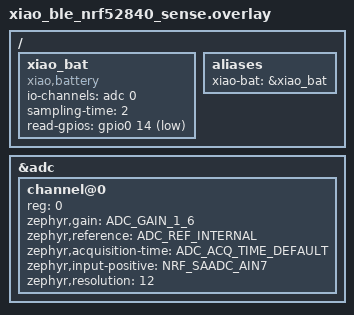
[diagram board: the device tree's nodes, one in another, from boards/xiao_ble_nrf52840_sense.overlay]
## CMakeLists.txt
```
# SPDX-License-Identifier: Apache-2.0

cmake_minimum_required(VERSION 3.20.0)
list(APPEND ZEPHYR_EXTRA_MODULES ${CMAKE_CURRENT_SOURCE_DIR}/../drivers)
find_package(Zephyr REQUIRED HINTS $ENV{ZEPHYR_BASE})
target_include_directories(app PRIVATE ${CMAKE_CURRENT_SOURCE_DIR}/../include)

project(project-helm)

if(DEFINED ID)
    zephyr_compile_definitions(NODE_ID=${ID})
endif()

FILE(GLOB app_sources src/*.c)
target_sources(app PRIVATE
    ${app_sources}
)
```

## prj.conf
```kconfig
# Bluetooth stuff
CONFIG_BT=y
CONFIG_BT_PERIPHERAL=y      # for NUS
CONFIG_BT_ZEPHYR_NUS=y      # for NUS
CONFIG_BT_OBSERVER=y        # for scanning
CONFIG_BT_BROADCASTER=y
CONFIG_BT_EXT_ADV=y

CONFIG_BT_FILTER_ACCEPT_LIST=y # Filtering
CONFIG_BT_MAX_CONN=1

CONFIG_BT_USER_DATA_LEN_UPDATE=y
CONFIG_BT_CTLR_DATA_LENGTH_MAX=251
CONFIG_BT_BUF_ACL_RX_SIZE=251
CONFIG_BT_BUF_ACL_TX_SIZE=251
CONFIG_BT_L2CAP_TX_MTU=247

# Power management
CONFIG_REBOOT=y
CONFIG_PM_DEVICE=y
CONFIG_PM_DEVICE_RUNTIME=y

# LSM6DSL Accelerometer
CONFIG_SENSOR=y
CONFIG_I2C=y
CONFIG_LSM6DSL_TRIGGER_GLOBAL_THREAD=y

# Xiao Battery Sensor
CONFIG_ADC=y
CONFIG_XIAO_BATTERY=y
CONFIG_CBPRINTF_FP_SUPPORT=y

# CRC tools to ensure validty of packets
CONFIG_CRC=y

CONFIG_POSIX_API=y
```

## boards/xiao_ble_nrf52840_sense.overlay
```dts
#include <zephyr/dt-bindings/adc/nrf-saadc.h>
#include <zephyr/dt-bindings/adc/adc.h>

/ {
	xiao_bat: xiao_bat {
		compatible = "xiao,battery";
		status = "okay";
		io-channels = <&adc 0>;
		sampling-time = <2>; /* This is in seconds */
		read-gpios = <&gpio0 14 GPIO_ACTIVE_LOW>;
	};

	aliases {
		xiao-bat = &xiao_bat;
	};
};

&adc {
	#address-cells = <1>;
	#size-cells = <0>;

	channel@0 {
		reg = <0>;
		zephyr,gain = "ADC_GAIN_1_6";
		zephyr,reference = "ADC_REF_INTERNAL";
		zephyr,acquisition-time = <ADC_ACQ_TIME_DEFAULT>;
		zephyr,input-positive = <NRF_SAADC_AIN7>;
		zephyr,resolution = <12>;
	};
};
```

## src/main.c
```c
/*
 * Copyright (c) 2026 Jack Cairns, Eden Mehr, Muhammed Abdilrahmin
 *
 * SPDX-License-Identifier: Apache-2.0
 */

#include <zephyr/kernel.h>
#include <zephyr/sys/reboot.h>

#include "gatt.h"
#include "imu.h"
#include <stdint.h>

/* ========================================================================== */
/* Main                                                                       */
/* ========================================================================== */

int main(void)
{
    printk("[INFO] CSSE4011 Project %s Chip\r\n", DEVICE_NAME);

    if (initialise_imu()) {
        goto reboot;
    }

    if (initialise_helm_gatt()) {
        goto reboot;
    }

    printk("[INFO] Mobile node initialization complete\n");
    uint8_t timeout = 0;
    while (1) {
        (am_i_connected()) ? timeout = 0 : timeout++;
        if (timeout >= 30) {
            goto reboot;
        }

        k_sleep(K_SECONDS(1));
    }
    
    return (0);

reboot:
    // sys_reboot doesn't return
    sys_reboot(SYS_REBOOT_WARM);
    return (-1);
}
```

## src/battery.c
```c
/*
 * Copyright (c) 2026 Jack Cairns, Eden Mehr, Muhammed Abdilrahmin
 *
 * SPDX-License-Identifier: Apache-2.0
 */

#include "battery.h"

#include <zephyr/device.h>
#include <zephyr/drivers/sensor.h>

/* ========================================================================== */
/* Devices                                                                    */
/* ========================================================================== */

static const struct device *const xiao_battery = DEVICE_DT_GET_ONE(xiao_battery);

/* ========================================================================== */
/* Initialisation and settings                                                */
/* ========================================================================== */

int get_battery_voltage(double *value)
{
    if (!device_is_ready(xiao_battery)) {
        printk("[ERROR] Unable to get xiao battery\n");
        return (-1);
    }

    struct sensor_value sensor_voltage;
    sensor_sample_fetch_chan(xiao_battery, SENSOR_CHAN_VOLTAGE);
    sensor_channel_get(xiao_battery, SENSOR_CHAN_VOLTAGE, &sensor_voltage);

    *value = sensor_value_to_double(&sensor_voltage);
    return (0);
}

int get_battery_charge(int32_t *value)
{
    if (!device_is_ready(xiao_battery)) {
        printk("[ERROR] Unable to get xiao battery\n");
        return (-1);
    }

    struct sensor_value sensor_charge;
    sensor_sample_fetch_chan(xiao_battery, SENSOR_CHAN_GAUGE_STATE_OF_CHARGE);
    sensor_channel_get(xiao_battery, SENSOR_CHAN_GAUGE_STATE_OF_CHARGE, &sensor_charge);

    *value = sensor_charge.val1;
    return (0);
}
```

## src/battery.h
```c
/*
 * Copyright (c) 2026 Jack Cairns, Eden Mehr, Muhammed Abdilrahmin
 *
 * SPDX-License-Identifier: Apache-2.0
 */

#ifndef BATTERY_H
#define BATTERY_H

#include <zephyr/kernel.h>

int get_battery_voltage(double *value);
int get_battery_charge(int32_t *value);

#endif
```

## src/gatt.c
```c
/*
 * Copyright (c) 2026 Jack Cairns, Eden Mehr, Muhammed Abdilrahmin
 *
 * SPDX-License-Identifier: Apache-2.0
 */

#include "gatt.h"

#include "imu.h"
#include "mac.h"
#include "common.h"

#include <zephyr/bluetooth/bluetooth.h>
#include <zephyr/bluetooth/services/nus.h>
#include <zephyr/kernel.h>
#include <zephyr/sys/printk.h>

#define ACK_TIMEOUT K_SECONDS(10)

/* ========================================================================== */
/* Workqueues for timeout/readvertising                                       */
/* ========================================================================== */

static struct k_work adv_restart_work;
static struct k_work_delayable timeout_work;

K_SEM_DEFINE(notif_sem, 0, 1);

/* ========================================================================== */
/* Current BLE connection                                                     */
/* ========================================================================== */

static struct bt_conn *current_conn = NULL;
static struct bt_le_adv_param adv_param;
static uint64_t connect_time = 0;

/* ========================================================================== */
/* Advertising Data                                                           */
/* ========================================================================== */

static const struct bt_data ad[] = {
    BT_DATA_BYTES(BT_DATA_FLAGS, (BT_LE_AD_GENERAL | BT_LE_AD_NO_BREDR)),
    BT_DATA(BT_DATA_NAME_COMPLETE, DEVICE_NAME, DEVICE_NAME_LEN),
};

static const struct bt_data sd[] = {
    BT_DATA_BYTES(BT_DATA_UUID128_ALL, BT_UUID_NUS_SRV_VAL),
};

/* ========================================================================== */
/* Static MAC                                                                 */
/* ========================================================================== */

static int set_static_address(void)
{
#ifndef NODE_ID
#error "NODE ID not found"
#endif

    int slot = NODE_ID;

    int err = bt_id_create((bt_addr_le_t *)&helm_addr[slot], NULL);
    if (err < 0) {
        printk("[ERROR] Failed to create identity: %d\n", err);
        return err;
    }

    return 0;
}

#ifdef WHITELIST
/* ========================================================================== */
/* Whitelist / Filter Accept List                                             */
/* ========================================================================== */

static int configure_accept_list(void)
{
    int err = bt_le_filter_accept_list_clear();
    if (err) {
        printk("[ERROR] Failed to clear accept list (err %d)\n", err);
        return err;
    }

    err = bt_le_filter_accept_list_add(&base_addr);
    if (err) {
        printk("[ERROR] Failed to add base to accept list (err %d)\n", err);
        return err;
    }

    printk("[INFO] Accept list configured\n");
    return 0;
}
#endif

/* ========================================================================== */
/* NUS Callbacks                                                              */
/* ========================================================================== */

static void notif_enabled(bool enabled, void *ctx)
{
    ARG_UNUSED(ctx);
    ARG_UNUSED(enabled);
}

static void received(struct bt_conn *conn, const void *data, uint16_t len, void *ctx)
{
    ARG_UNUSED(ctx);
    ARG_UNUSED(conn);
    ARG_UNUSED(len);

    struct cmd_ble_packet *packet = (struct cmd_ble_packet *)data;
    if (packet->cmd == 1) {
        set_absolute_time(packet->time);
        printk("[INFO] TIME SET %lld\n", packet->time);
    }

    k_sem_give(&notif_sem);
    k_work_reschedule(&timeout_work, ACK_TIMEOUT);
}

struct bt_nus_cb nus_listener = {
    .notif_enabled = notif_enabled,
    .received = received,
};

/* ========================================================================== */
/* BLE Gatt Disconnection timeout                                             */
/* ========================================================================== */

static void disconnect_timeout(struct k_work *work)
{
    if (current_conn != NULL) {
        printk("[INFO] Connection timeout, disconnecting\n");
        bt_conn_disconnect(current_conn, BT_HCI_ERR_REMOTE_USER_TERM_CONN);
    }
}

static void adv_restart(struct k_work *work)
{
    int err = bt_le_adv_start(&adv_param, ad, ARRAY_SIZE(ad), sd, ARRAY_SIZE(sd));
    if (err < 0) {
        printk("[ERROR] Failed to restart advertising (err %d)\n", err);
        return;
    }

    printk("[INFO] NUS Advertising restarted\n");
}

/* ========================================================================== */
/* BLE Gatt Connection and Disconnection callbacks                            */
/* ========================================================================== */

static void connected(struct bt_conn *conn, uint8_t err)
{
    if (err) {
        return;
    }

    current_conn = bt_conn_ref(conn);
    connect_time = k_uptime_get();
    printk("[INFO] Connected\n");

    // Turn on the IMU now that ble is connected
    resume_imu();

    /* Start timeout watchdog - 10 seconds */
    k_work_reschedule(&timeout_work, ACK_TIMEOUT);
}

static void disconnected(struct bt_conn *conn, uint8_t reason)
{
    uint64_t duration = k_uptime_get() - connect_time;
    printk("[WARN] Disconnected (reason 0x%02x) after %llu ms\n", reason, duration);

    if (current_conn) {
        bt_conn_unref(current_conn);
        current_conn = NULL;
    }

    k_work_cancel_delayable(&timeout_work);

    // Turn off the IMU as ble is not connected anymore
    susspend_imu();

    /* Restart advertising so base can reconnect */
    k_work_submit(&adv_restart_work);
}

BT_CONN_CB_DEFINE(conn_callbacks) = {
    .connected = connected,
    .disconnected = disconnected,
};

/* ========================================================================== */
/* MTU callbacks                                                              */
/* ========================================================================== */

static void mtu_updated(struct bt_conn *conn, uint16_t tx, uint16_t rx)
{
    // Display new MTU values (buffer size for NUS)
    printk("[INFO] Updated MTU, TX: %d, RX: %d\n", tx, rx);
}

static struct bt_gatt_cb gatt_callbacks = {.att_mtu_updated = mtu_updated};

/* ========================================================================== */
/* GATT intialisation procedure                                               */
/* ========================================================================== */

int initialise_helm_gatt(void)
{
    if (set_static_address()) {
        printk("[ERROR] Failed to set static MAC\n");
        return (-1);
    }

    // Register NUS callbacks before bt_enable
    int err = bt_nus_cb_register(&nus_listener, NULL);
    if (err) {
        printk("[ERROR] Failed to register NUS callback: %d\n", err);
        return (err);
    }

    // These are added to the default Zephyr System Work Queue
    // Delayed work task for restarting ble advertising
    k_work_init(&adv_restart_work, adv_restart);
    // Delayed timer task to auto disconnect the GATT if no NUS sends occur in 10s
    k_work_init_delayable(&timeout_work, disconnect_timeout);

    // Enable bluetooth
    err = bt_enable(NULL);
    if (err) {
        printk("[ERROR] Failed to enable bluetooth: %d\n", err);
        return (err);
    }

    // Setup the NUS ad params
    adv_param = *BT_LE_ADV_CONN_FAST_1;

#ifdef WHITELIST
    // Accept list must be configured after bt_enable
    if (configure_accept_list()) {
        printk("[ERROR] Failed to configure accept list\n");
        return (-1);
    }

    // Add white-list options if filtering
    adv_param.options |= BT_LE_ADV_OPT_FILTER_CONN | BT_LE_ADV_OPT_FILTER_SCAN_REQ;
#endif

    // New MTU size
    bt_gatt_cb_register(&gatt_callbacks);

    // Start NUS advertising so base chip can connect
    err = bt_le_adv_start(&adv_param, ad, ARRAY_SIZE(ad), sd, ARRAY_SIZE(sd));
    if (err) {
        printk("[ERROR] Failed to start advertising: %d\n", err);
        return (err);
    }

    return 0;
}

uint8_t am_i_connected(void)
{
    return current_conn != NULL;
}

int send_data_nus(const void *data, uint16_t len)
{
    if (current_conn == NULL) {
        return (-1);
    }

    int ret = bt_nus_send(NULL, data, len);
    if (ret == 0) {
        k_work_reschedule(&timeout_work, ACK_TIMEOUT);
    } else {
        printk("[ERROR] Failed to send packet: %d\nPointer: %p Size: %d\n", ret, data, len);
    }

    return (ret);
}
```

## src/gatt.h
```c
/*
 * Copyright (c) 2026 Jack Cairns, Eden Mehr, Muhammed Abdilrahmin
 *
 * SPDX-License-Identifier: Apache-2.0
 */

#ifndef GATT_H
#define GATT_H

#define WHITELIST // Enables connection whitelisting

#if (NODE_ID == 0)
#define DEVICE_NAME "Helm-A"
#elif (NODE_ID == 1)
#define DEVICE_NAME "Helm-B"
#endif

#define DEVICE_NAME_LEN (sizeof(DEVICE_NAME) - 1)

#include <zephyr/kernel.h>

extern struct k_sem notif_sem;

int initialise_helm_gatt(void);
int send_data_nus(const void *data, uint16_t len);
uint8_t am_i_connected(void);

#endif
```

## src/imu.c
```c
/*
 * Copyright (c) 2026 Jack Cairns, Eden Mehr, Muhammed Abdilrahmin
 *
 * SPDX-License-Identifier: Apache-2.0
 */

#include "imu.h"

#include "common.h"

#include "zephyr/kernel.h"
#include "zephyr/sys/atomic.h"
#include "zephyr/sys/printk.h"
#include <zephyr/device.h>
#include <zephyr/drivers/sensor.h>
#include <zephyr/pm/device_runtime.h>

#define SAMPLING_FREQ 416
#define GYRO_RANGE    1000

/* ********************************************************************************************* */
/* Constants                                                                                     */
/* ********************************************************************************************* */

static const struct device *const lsm6dsl_dev = DEVICE_DT_GET_ONE(st_lsm6dsl);

/* ********************************************************************************************* */
/* State                                                                                         */
/* ********************************************************************************************* */

/* Message queue of depth 1 - we are only interested in the last item. */
K_MSGQ_DEFINE(imu_q, sizeof(struct imu_data), 1, 1);

static atomic_t pm_enable = ATOMIC_INIT(0);

/* ********************************************************************************************* */
/* Functions                                                                                     */
/* ********************************************************************************************* */

static void lsm6dsl_trigger_handler(const struct device *dev, const struct sensor_trigger *trig)
{
    struct sensor_value accel_x;
    struct sensor_value gyro_z;

    sensor_sample_fetch_chan(dev, SENSOR_CHAN_ACCEL_XYZ);
    sensor_sample_fetch_chan(dev, SENSOR_CHAN_GYRO_XYZ);

    sensor_channel_get(dev, SENSOR_CHAN_ACCEL_X, &accel_x);
    sensor_channel_get(dev, SENSOR_CHAN_GYRO_Z, &gyro_z);

    // Either ms since boot or current internet time
    int64_t current = get_time();
    struct imu_data data = {.gyro_rads = sensor_value_to_double(&gyro_z),
                            .accel_ms2 = sensor_value_to_double(&accel_x),
                            .timestamp = current};

    // We are only interested in the last item.
    while (k_msgq_put(&imu_q, &data, K_NO_WAIT) != 0) {
        k_msgq_purge(&imu_q);
    }
}

int initialise_imu(void)
{
    if (!device_is_ready(lsm6dsl_dev)) {
        printk("[ERROR] LSM6DSL: device not ready\n");
        return (-ENODEV);
    }

    if (pm_device_runtime_enable(lsm6dsl_dev) < 0) {
        printk("[WARN] LSM6DSL: runtime pm init fail\n");
    } else {
        atomic_set(&pm_enable, 1);
    }

    // Only soft initialise the imu here. Just really checking that the device exists
    return (0);
}

int susspend_imu(void)
{
    if (!atomic_get(&pm_enable)) {
        return (-ENOTSUP);
    }

    int ret = pm_device_runtime_put(lsm6dsl_dev);
    if (ret < 0) {
        printk("[ERROR] LSM6DSL: IMU suspend failed\n");
        return (ret);
    }

    printk("[INFO] LSM6DSL: IMU suspended\n");
    return (0);
}

int resume_imu(void)
{
    // Set sampling frequency to 416Hz.
    const struct sensor_value frequency_attr = {.val1 = SAMPLING_FREQ, .val2 = 0};
    const struct sensor_trigger trig = {.type = SENSOR_TRIG_DATA_READY,
                                        .chan = SENSOR_CHAN_ACCEL_XYZ};
    struct sensor_value gyro_fs_attr;

    // Safe to call when not enabled -> results in a NO-OP
    int ret = pm_device_runtime_get(lsm6dsl_dev);
    if (ret < 0) {
        printk("[ERROR] LSM6DSL: runtime get fail\n");
        return (ret);
    }

    // Actually initialise the IMU
    ret = sensor_attr_set(lsm6dsl_dev, SENSOR_CHAN_ACCEL_XYZ, SENSOR_ATTR_SAMPLING_FREQUENCY,
                          &frequency_attr);
    if (ret < 0) {
        printk("[ERROR] Cannot set sampling frequency for accelerometer (%d)\n", ret);
        return (ret);
    }

    ret = sensor_attr_set(lsm6dsl_dev, SENSOR_CHAN_GYRO_XYZ, SENSOR_ATTR_SAMPLING_FREQUENCY,
                          &frequency_attr);
    if (ret < 0) {
        printk("[ERROR] Cannot set sampling frequency for gyroscope (%d)\n", ret);
        return (ret);
    }

    sensor_degrees_to_rad(GYRO_RANGE, &gyro_fs_attr);
    ret = sensor_attr_set(lsm6dsl_dev, SENSOR_CHAN_GYRO_XYZ, SENSOR_ATTR_FULL_SCALE, &gyro_fs_attr);
    if (ret < 0) {
        printk("[ERROR] Cannot set gyroscope full-scale range (%d)\n", ret);
        return (ret);
    }

    ret = sensor_trigger_set(lsm6dsl_dev, &trig, lsm6dsl_trigger_handler);
    if (ret != 0) {
        printk("[ERROR] Could not set sensor type and channel (%d)\n", ret);
        return (ret);
    }

    ret = sensor_sample_fetch(lsm6dsl_dev);
    if (ret < 0) {
        printk("[ERROR] Sensor sample update error\n (%d)", ret);
        return (ret);
    }

    printk("[INFO] LSM6DSL: IMU resumed\n");
    return (0);
}
```

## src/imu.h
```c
/*
 * Copyright (c) 2026 Jack Cairns, Eden Mehr, Muhammed Abdilrahmin
 *
 * SPDX-License-Identifier: Apache-2.0
 */

#ifndef IMU_H
#define IMU_H

#include <zephyr/kernel.h>

extern struct k_msgq imu_q;

int initialise_imu(void);
int susspend_imu(void);
int resume_imu(void);

#endif
```

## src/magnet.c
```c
// /*
//  * Copyright (c) 2026 Jack Cairns, Eden Mehr, Muhammed Abdilrahmin
//  *
//  * SPDX-License-Identifier: Apache-2.0
//  */

// #include "magnet.h"

// #include <zephyr/device.h>
// #include <zephyr/drivers/gpio.h>

// /* Message queue of depth 1 - we are only interested in the last item. */
// K_MSGQ_DEFINE(magnet_time_q, sizeof(int64_t), 1, 1);

// /* Magnet pin interrupt - for hall effect or reed switch */
// static const struct gpio_dt_spec magnet_pin = GPIO_DT_SPEC_GET(DT_ALIAS(magnet_pin), gpios);

// static struct gpio_callback magnet_cb_data;

// /* Callback function on pin interrupt */
// static void magnet_pin_cb(const struct device *dev, struct gpio_callback *cb, uint32_t pins)
// {
//     int64_t current_time_ms = k_uptime_get();

//     // Try to add the currnet time - if the queue is full, purge it and try again
//     while (k_msgq_put(&magnet_time_q, &current_time_ms, K_NO_WAIT) != 0) {
//         k_msgq_purge(&magnet_time_q);
//     }
// }

// int initialise_magnet_sensor(void)
// {
//     int ret;

//     if (!gpio_is_ready_dt(&magnet_pin)) {
//         printk("Error: magnet_pin device %s is not ready\n", magnet_pin.port->name);
//         return -ENODEV;
//     }

//     ret = gpio_pin_configure_dt(&magnet_pin, GPIO_INPUT);
//     if (ret != 0) {
//         printk("Error %d: failed to configure %s pin %d\n", ret, magnet_pin.port->name,
//                magnet_pin.pin);
//         return ret;
//     }

//     ret = gpio_pin_interrupt_configure_dt(&magnet_pin, GPIO_INT_EDGE_TO_ACTIVE);
//     if (ret != 0) {
//         printk("Error %d: failed to configure interrupt on %s pin %d\n", ret, magnet_pin.port->name,
//                magnet_pin.pin);
//         return ret;
//     }

//     gpio_init_callback(&magnet_cb_data, magnet_pin_cb, BIT(magnet_pin.pin));
//     ret = gpio_add_callback(magnet_pin.port, &magnet_cb_data);
//     if (ret != 0) {
//         printk("Error %d: failed to configure callback on %s pin %d\n", ret, magnet_pin.port->name,
//                magnet_pin.pin);
//         return ret;
//     }

//     return 0;
// }
```

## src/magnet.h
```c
// /*
//  * Copyright (c) 2026 Jack Cairns, Eden Mehr, Muhammed Abdilrahmin
//  *
//  * SPDX-License-Identifier: Apache-2.0
//  */

// #ifndef MAGNET_H
// #define MAGNET_H

// #include <zephyr/kernel.h>

// extern struct k_msgq magnet_time_q;

// int initialise_magnet_sensor(void);

// #endif
```

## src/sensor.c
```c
/*
 * Copyright (c) 2026 Jack Cairns, Eden Mehr, Muhammed Abdilrahmin
 *
 * SPDX-License-Identifier: Apache-2.0
 */

#include "sensor.h"

// Shit for the sensors
```

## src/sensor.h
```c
/*
 * Copyright (c) 2026 Jack Cairns, Eden Mehr, Muhammed Abdilrahmin
 *
 * SPDX-License-Identifier: Apache-2.0
 */

#ifndef SENSOR_H
#define SENSOR_H

#endif
```

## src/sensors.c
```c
/*
 * Copyright (c) 2026 Jack Cairns, Eden Mehr, Muhammed Abdilrahmin
 *
 * SPDX-License-Identifier: Apache-2.0
 */

#include "common.h"

#include "battery.h"
#include "gatt.h"
#include "imu.h"

#include <zephyr/kernel.h>
#include <zephyr/sys/crc.h>

#define BAT_PACKET_PERIOD_MS 9000
#define PRIORITY             3
#define STACK_SIZE           2048

#if (NODE_ID == 0)
#define NODE_NUM 0
#elif (NODE_ID == 1)
#define NODE_NUM 1
#endif

// Initialied here, extern'ed in common.h
atomic_t is_time_set = ATOMIC_INIT(0);

/* ========================================================================== */
/* Static Data                                                                */
/* ========================================================================== */

static struct ble_packet bat_packet = {.packet_id = BATTERY, .node_num = NODE_NUM, .crc16 = 0};
static struct ble_packet sensor_packet = {.packet_id = SENSOR, .node_num = NODE_NUM, .crc16 = 0};

/* ========================================================================== */
/* Send data packet for sensor data & battery voltage                         */
/* ========================================================================== */

static void send_sensor_thread(void *arg1, void *arg2, void *arg3)
{
    ARG_UNUSED(arg1);
    ARG_UNUSED(arg2);
    ARG_UNUSED(arg3);

    int64_t last_bat_reading = 0;
    double *mv = &bat_packet.data.bat.bat_mv;
    int32_t *charge = &bat_packet.data.bat.bat_charge;
    time_t *bat_ts = &bat_packet.data.bat.timestamp;

    struct imu_data *imu_data = &sensor_packet.data.imu;

    while (1) {
        k_sem_take(&notif_sem, K_FOREVER);

        // Collect IMU Data
        k_msgq_get(&imu_q, imu_data, K_NO_WAIT);
        sensor_packet.crc16 = crc16_ansi((char *)&(sensor_packet.data), sizeof(union ble_data));

        // Send to Base
        send_data_nus(&sensor_packet, sizeof(sensor_packet));

        // Send Battery Data every BAT_PACKET_PERIOD_MS
        int64_t now = k_uptime_get();
        if ((now - last_bat_reading) < BAT_PACKET_PERIOD_MS) {
            continue;
        }

        // Collect battery data
        last_bat_reading = now;
        *bat_ts = get_time();
        get_battery_charge(charge);
        get_battery_voltage(mv);

        bat_packet.crc16 = crc16_ansi((char *)&(bat_packet.data), sizeof(union ble_data));

        // Send to base
        send_data_nus(&bat_packet, sizeof(bat_packet));
    }
}

K_THREAD_DEFINE(send_sensor, STACK_SIZE, send_sensor_thread, NULL, NULL, NULL, PRIORITY, 0, 0);
```
